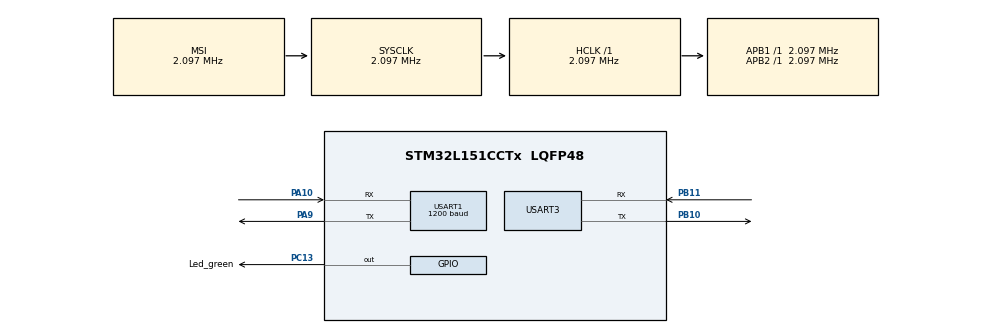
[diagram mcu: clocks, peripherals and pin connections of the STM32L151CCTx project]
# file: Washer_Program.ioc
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Dma.Request0=USART1_RX
Dma.Request1=USART1_TX
Dma.USART1_RX.0.Direction=DMA_PERIPH_TO_MEMORY
Dma.USART1_RX.0.Instance=DMA1_Channel5
Dma.USART1_RX.0.MemDataAlignment=DMA_MDATAALIGN_BYTE
Dma.USART1_RX.0.MemInc=DMA_MINC_ENABLE
Dma.USART1_RX.0.Mode=DMA_NORMAL
Dma.USART1_RX.0.PeriphDataAlignment=DMA_PDATAALIGN_BYTE
Dma.USART1_RX.0.PeriphInc=DMA_PINC_DISABLE
Dma.USART1_RX.0.Priority=DMA_PRIORITY_LOW
Dma.USART1_TX.1.Direction=DMA_MEMORY_TO_PERIPH
Dma.USART1_TX.1.Instance=DMA1_Channel4
Dma.USART1_TX.1.MemDataAlignment=DMA_MDATAALIGN_BYTE
Dma.USART1_TX.1.MemInc=DMA_MINC_ENABLE
Dma.USART1_TX.1.Mode=DMA_NORMAL
Dma.USART1_TX.1.PeriphDataAlignment=DMA_PDATAALIGN_BYTE
Dma.USART1_TX.1.PeriphInc=DMA_PINC_DISABLE
Dma.USART1_TX.1.Priority=DMA_PRIORITY_LOW
Mcu.Family=STM32L1
Mcu.Name=STM32L151CCTx
Mcu.Package=LQFP48
NVIC.DMA1_Channel4_IRQn=true\:0\:0\:false\:false\:true\:true\:false\:true
NVIC.DMA1_Channel5_IRQn=true\:0\:0\:false\:false\:true\:true\:false\:true
NVIC.PriorityGroup=NVIC_PRIORITYGROUP_4
NVIC.USART1_IRQn=true\:0\:0\:false\:false\:true\:false\:true\:true
PA10.Mode=Asynchronous
PA10.Signal=USART1_RX
PA13.Mode=Serial_Wire
PA13.Signal=SYS_JTMS-SWDIO
PA14.Mode=Serial_Wire
PA14.Signal=SYS_JTCK-SWCLK
PA9.Mode=Asynchronous
PA9.Signal=USART1_TX
PB10.Mode=Asynchronous
PB10.Signal=USART3_TX
PB11.Mode=Asynchronous
PB11.Signal=USART3_RX
PC13-WKUP2.GPIO_Label=Led_green
PC13-WKUP2.PinState=GPIO_PIN_SET
PC13-WKUP2.Signal=GPIO_Output
PC14-OSC32_IN.Mode=LSE-External-Oscillator
PC14-OSC32_IN.Signal=RCC_OSC32_IN
PC15-OSC32_OUT.Mode=LSE-External-Oscillator
PC15-OSC32_OUT.Signal=RCC_OSC32_OUT
PH0-OSC_IN.Mode=HSE-External-Oscillator
PH0-OSC_IN.Signal=RCC_OSC_IN
PH1-OSC_OUT.Mode=HSE-External-Oscillator
PH1-OSC_OUT.Signal=RCC_OSC_OUT
ProjectManager.HeapSize=0x200
ProjectManager.StackSize=0x400
ProjectManager.TargetToolchain=MDK-ARM V5.27
RCC.AHBFreq_Value=2097000
RCC.APB1Freq_Value=2097000
RCC.APB2Freq_Value=2097000
RCC.HSE_VALUE=24000000
RCC.HSI_VALUE=16000000
RCC.MSI_VALUE=2097000
RCC.SYSCLKFreq_VALUE=2097000
RCC.VCOOutputFreq_Value=48000000
RealThread.RT-Thread.3.1.3.RTAaThreadCcRTOSJjkernel=true
RealThread.RT-Thread.3.1.3.RTAaThreadCcRTOSJjshell=true
USART1.BaudRate=1200
USART1.VirtualMode=VM_ASYNC
USART3.VirtualMode=VM_ASYNC
VP_RealThread.RT-Thread_VS_RTOSJjRTAaThread_3.1.3.Mode=RTOSJjRTAaThread
board=custom

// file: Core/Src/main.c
/* USER CODE BEGIN Header */
/**
  ******************************************************************************
  * @file           : main.c
  * @brief          : Main program body
  ******************************************************************************
  * @attention
  *
  * <h2><center>&copy; Copyright (c) 2021 STMicroelectronics.
  * All rights reserved.</center></h2>
  *
  * This software component is licensed by ST under Ultimate Liberty license
  * SLA0044, the "License"; You may not use this file except in compliance with
  * the License. You may obtain a copy of the License at:
  *                             www.st.com/SLA0044
  *
  ******************************************************************************
  */
/* USER CODE END Header */
#include "main.h"
#include "dma.h"
#include "usart.h"
#include "gpio.h"
#include "task.h"
#include "iwdg.h"

void SystemClock_Config(void);

int main(void)
{
  /* USER CODE BEGIN 1 */
	static uint32_t MainLoopCnt = 0;
  /* USER CODE END 1 */

  /* MCU Configuration--------------------------------------------------------*/

  /* Reset of all peripherals, Initializes the Flash interface and the Systick. */

  /* Configure the system clock */

  /* Initialize all configured peripherals */
  /* USER CODE BEGIN 2 */
	TaskInit();
  /* USER CODE END 2 */

  /* Infinite loop */
  /* USER CODE BEGIN WHILE */
  while (1)
  {

		if(MainLoopCnt == 0)
		{
			Start_IWDG();
		}
		if(MainLoopCnt % 10 == 0)			// 1s FeedDog
		{
			Feed_Dog();
		}
		rt_thread_delay(100);   /* 延时500个tick */
  }
}

void SystemClock_Config(void)
{
  RCC_OscInitTypeDef RCC_OscInitStruct = {0};
  RCC_ClkInitTypeDef RCC_ClkInitStruct = {0};

  /** Configure the main internal regulator output voltage
  */
  __HAL_PWR_VOLTAGESCALING_CONFIG(PWR_REGULATOR_VOLTAGE_SCALE1);
  /** Initializes the RCC Oscillators according to the specified parameters
  * in the RCC_OscInitTypeDef structure.
  */
  RCC_OscInitStruct.OscillatorType = RCC_OSCILLATORTYPE_MSI;
  RCC_OscInitStruct.MSIState = RCC_MSI_ON;
  RCC_OscInitStruct.MSICalibrationValue = 0;
  RCC_OscInitStruct.MSIClockRange = RCC_MSIRANGE_5;
  RCC_OscInitStruct.PLL.PLLState = RCC_PLL_NONE;
  if (HAL_RCC_OscConfig(&RCC_OscInitStruct) != HAL_OK)
  {
    Error_Handler();
  }
  /** Initializes the CPU, AHB and APB buses clocks
  */
  RCC_ClkInitStruct.ClockType = RCC_CLOCKTYPE_HCLK|RCC_CLOCKTYPE_SYSCLK
                              |RCC_CLOCKTYPE_PCLK1|RCC_CLOCKTYPE_PCLK2;
  RCC_ClkInitStruct.SYSCLKSource = RCC_SYSCLKSOURCE_MSI;
  RCC_ClkInitStruct.AHBCLKDivider = RCC_SYSCLK_DIV1;
  RCC_ClkInitStruct.APB1CLKDivider = RCC_HCLK_DIV1;
  RCC_ClkInitStruct.APB2CLKDivider = RCC_HCLK_DIV1;

  if (HAL_RCC_ClockConfig(&RCC_ClkInitStruct, FLASH_LATENCY_0) != HAL_OK)
  {
    Error_Handler();
  }
}

/* USER CODE BEGIN 4 */
void sys_init(void)
{
  HAL_Init();
  SystemClock_Config();
	MX_GPIO_Init();
  MX_DMA_Init();
  MX_USART1_UART_Init();
  MX_USART3_UART_Init();
	MX_IWDG_Init();
	printf("printfceshidayin！！\r\n");
	rt_kprintf("rt_kprintfceshidayin！\r\n");
}
/* USER CODE END 4 */

void Error_Handler(void)
{
}

/************************ (C) COPYRIGHT STMicroelectronics *****END OF FILE****/
